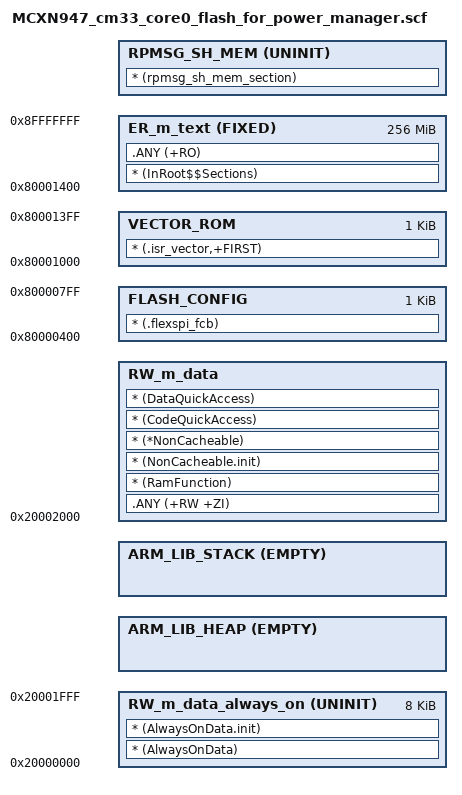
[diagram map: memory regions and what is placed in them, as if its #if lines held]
#!armclang --target=arm-arm-none-eabi -march=armv8-m.main -E -x c
/*
 * Copyright 2024 NXP
 *
 * SPDX-License-Identifier: BSD-3-Clause
 */

/* Sizes */
#if (defined(__stack_size__))
  #define Stack_Size                   __stack_size__
#else
  #define Stack_Size                   0x0400
#endif

#if (defined(__heap_size__))
  #define Heap_Size                    __heap_size__
#else
  #define Heap_Size                    0x0400
#endif

#if (defined(__qspi_xip__))
  #define  m_interrupts_start            0x80001000
  #define  m_interrupts_size             0x00000400

  #define  m_text_start                  0x80001400
  #define  m_text_size                   0x0FFFEC00
#else
  #define  m_interrupts_start            0x00000000
  #define  m_interrupts_size             0x00000400

  #define  m_text_start                  0x00000400
  #define  m_text_size                   0x000BFC00
#endif

#define  m_flash1_start                0x00100000
#define  m_flash1_size                 0x00100000

#define  m_sramx_start                 0x04000000
#define  m_sramx_size                  0x00018000

#define  m_data_always_on_start        0x20000000
#define  m_data_always_on_size         0x00002000

#define  m_data_start                0x20002000
#define  m_data_size                 0x00006000

#define  m_boot_flash_conf_start       0x80000400

LR_m_flash_conf m_boot_flash_conf_start 0x400 {
  FLASH_CONFIG m_boot_flash_conf_start 0x400{ ; load address = execution address
    * (.flexspi_fcb)
  }
}

LR_m_text m_interrupts_start m_interrupts_size+m_text_size {   ; load region size_region

  VECTOR_ROM m_interrupts_start m_interrupts_size { ; load address = execution address
    * (.isr_vector,+FIRST)
  }

  ER_m_text m_text_start FIXED m_text_size { ; load address = execution address
    * (InRoot$$Sections)
    .ANY (+RO)
  }

#if (defined(__use_shmem__))
  RPMSG_SH_MEM m_rpmsg_sh_mem_start UNINIT m_rpmsg_sh_mem_size { ; Shared memory used by RPMSG
    * (rpmsg_sh_mem_section)
  }
#endif

  RW_m_data m_data_start m_data_size-Stack_Size-Heap_Size { ; RW data
    .ANY (+RW +ZI)
    * (RamFunction)
    * (NonCacheable.init)
    * (*NonCacheable)
    * (CodeQuickAccess)
    * (DataQuickAccess)
  }
  RW_m_data_always_on m_data_always_on_start UNINIT m_data_always_on_size { ; RW data
    * (AlwaysOnData)
    * (AlwaysOnData.init)
  }
  ARM_LIB_HEAP +0 EMPTY Heap_Size {    ; Heap region growing up
  }
  ARM_LIB_STACK m_data_start+m_data_size EMPTY -Stack_Size { ; Stack region growing down
  }
}
